VERSION "1.0 — BFMC CAN Bus Network"

NS_ :

BS_:

BU_: GATEWAY MOTION SENSOR LOGGER

BO_ 16 EMERGENCY_STOP: 2 Vector__XXX
 SG_ EStopSource : 0|8@1+ (1,0) [0|255] "" GATEWAY,MOTION,SENSOR,LOGGER
 SG_ EStopReason : 8|8@1+ (1,0) [0|255] "" GATEWAY,MOTION,SENSOR,LOGGER

BO_ 128 SAFETY_STATE: 2 GATEWAY
 SG_ ArmState : 0|8@1+ (1,0) [0|3] "" MOTION,SENSOR,LOGGER
 SG_ FaultFlags : 8|8@1+ (1,0) [0|255] "" MOTION,SENSOR,LOGGER

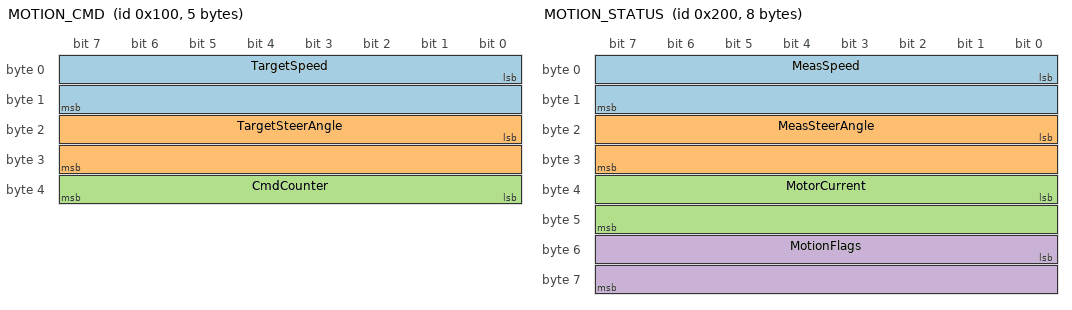
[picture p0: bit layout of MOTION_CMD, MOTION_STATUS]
BO_ 256 MOTION_CMD: 5 GATEWAY
 SG_ TargetSpeed : 0|16@1- (1,0) [-2000|2000] "mm/s" MOTION,LOGGER
 SG_ TargetSteerAngle : 16|16@1- (0.1,0) [-25|25] "deg" MOTION,LOGGER
 SG_ CmdCounter : 32|8@1+ (1,0) [0|255] "" MOTION,LOGGER

BO_ 512 MOTION_STATUS: 8 MOTION
 SG_ MeasSpeed : 0|16@1- (1,0) [-2000|2000] "mm/s" GATEWAY,LOGGER
 SG_ MeasSteerAngle : 16|16@1- (0.1,0) [-25|25] "deg" GATEWAY,LOGGER
 SG_ MotorCurrent : 32|16@1- (1,0) [-20000|20000] "mA" GATEWAY,LOGGER
 SG_ MotionFlags : 48|16@1+ (1,0) [0|65535] "" GATEWAY,LOGGER

BO_ 528 WHEEL_ENCODER: 8 MOTION
 SG_ EncoderTicks : 0|32@1- (1,0) [-2147483648|2147483647] "ticks" GATEWAY,LOGGER
 SG_ DistanceTravelled : 32|32@1- (1,0) [-2147483648|2147483647] "mm" GATEWAY,LOGGER

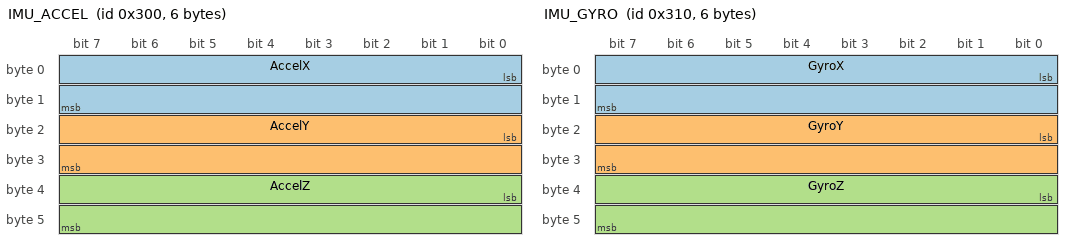
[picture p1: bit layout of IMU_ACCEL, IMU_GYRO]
BO_ 768 IMU_ACCEL: 6 SENSOR
 SG_ AccelX : 0|16@1- (1,0) [-8000|8000] "mg" GATEWAY,MOTION,LOGGER
 SG_ AccelY : 16|16@1- (1,0) [-8000|8000] "mg" GATEWAY,MOTION,LOGGER
 SG_ AccelZ : 32|16@1- (1,0) [-8000|8000] "mg" GATEWAY,MOTION,LOGGER

BO_ 784 IMU_GYRO: 6 SENSOR
 SG_ GyroX : 0|16@1- (0.1,0) [-2000|2000] "deg/s" GATEWAY,MOTION,LOGGER
 SG_ GyroY : 16|16@1- (0.1,0) [-2000|2000] "deg/s" GATEWAY,MOTION,LOGGER
 SG_ GyroZ : 32|16@1- (0.1,0) [-2000|2000] "deg/s" GATEWAY,MOTION,LOGGER

BO_ 800 IMU_ATTITUDE: 4 SENSOR
 SG_ Yaw : 0|16@1- (0.1,0) [-180|180] "deg" GATEWAY,MOTION,LOGGER
 SG_ YawRate : 16|16@1- (0.1,0) [-2000|2000] "deg/s" GATEWAY,MOTION,LOGGER

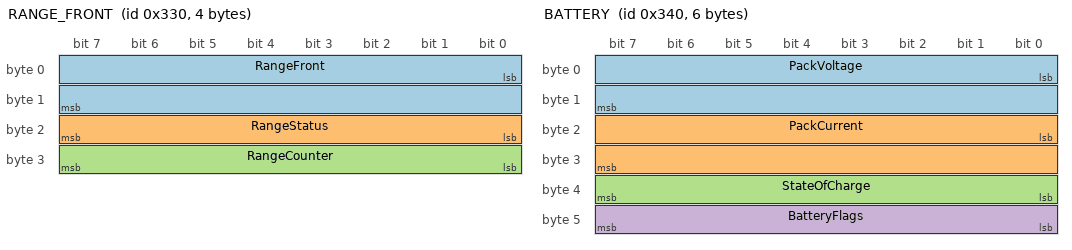
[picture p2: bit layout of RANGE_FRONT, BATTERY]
BO_ 816 RANGE_FRONT: 4 SENSOR
 SG_ RangeFront : 0|16@1+ (1,0) [0|4000] "mm" GATEWAY,MOTION,LOGGER
 SG_ RangeStatus : 16|8@1+ (1,0) [0|3] "" GATEWAY,MOTION,LOGGER
 SG_ RangeCounter : 24|8@1+ (1,0) [0|255] "" GATEWAY,MOTION,LOGGER

BO_ 832 BATTERY: 6 SENSOR
 SG_ PackVoltage : 0|16@1+ (1,0) [0|30000] "mV" GATEWAY,LOGGER
 SG_ PackCurrent : 16|16@1- (1,0) [-30000|30000] "mA" GATEWAY,LOGGER
 SG_ StateOfCharge : 32|8@1+ (1,0) [0|100] "%" GATEWAY,LOGGER
 SG_ BatteryFlags : 40|8@1+ (1,0) [0|255] "" GATEWAY,LOGGER

BO_ 1024 HB_GATEWAY: 2 GATEWAY
 SG_ GatewayHbCounter : 0|8@1+ (1,0) [0|255] "" MOTION,SENSOR,LOGGER
 SG_ GatewayNodeState : 8|8@1+ (1,0) [0|4] "" MOTION,SENSOR,LOGGER

BO_ 1025 HB_MOTION: 2 MOTION
 SG_ MotionHbCounter : 0|8@1+ (1,0) [0|255] "" GATEWAY,SENSOR,LOGGER
 SG_ MotionNodeState : 8|8@1+ (1,0) [0|4] "" GATEWAY,SENSOR,LOGGER

BO_ 1026 HB_SENSOR: 2 SENSOR
 SG_ SensorHbCounter : 0|8@1+ (1,0) [0|255] "" GATEWAY,MOTION,LOGGER
 SG_ SensorNodeState : 8|8@1+ (1,0) [0|4] "" GATEWAY,MOTION,LOGGER

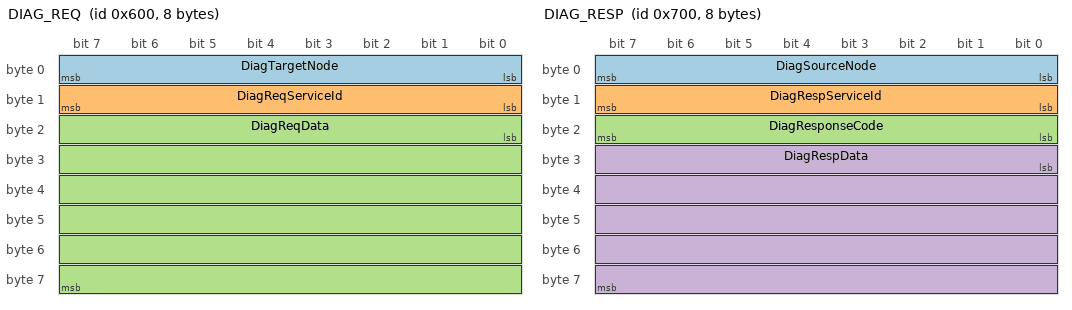
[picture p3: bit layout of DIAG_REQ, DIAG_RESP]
BO_ 1536 DIAG_REQ: 8 GATEWAY
 SG_ DiagTargetNode : 0|8@1+ (1,0) [0|255] "" MOTION,SENSOR,LOGGER
 SG_ DiagReqServiceId : 8|8@1+ (1,0) [0|255] "" MOTION,SENSOR,LOGGER
 SG_ DiagReqData : 16|48@1+ (1,0) [0|0] "" MOTION,SENSOR,LOGGER

BO_ 1792 DIAG_RESP: 8 Vector__XXX
 SG_ DiagSourceNode : 0|8@1+ (1,0) [0|255] "" GATEWAY,LOGGER
 SG_ DiagRespServiceId : 8|8@1+ (1,0) [0|255] "" GATEWAY,LOGGER
 SG_ DiagResponseCode : 16|8@1+ (1,0) [0|255] "" GATEWAY,LOGGER
 SG_ DiagRespData : 24|40@1+ (1,0) [0|0] "" GATEWAY,LOGGER

CM_ BO_ 16 "Broadcast emergency stop. Highest priority frame on the bus. Any node may originate.";
CM_ BO_ 128 "Vehicle-level arm state and aggregated fault bitfield, owned by the Gateway.";
CM_ BO_ 256 "Actuator setpoints. CmdCounter must advance every cycle or Motion rejects the frame as stale.";
CM_ BO_ 512 "Closed-loop feedback from the Motion ECU.";
CM_ BO_ 1536 "Diagnostic request, UDS-inspired. DiagTargetNode selects the addressed ECU.";
CM_ SG_ 256 CmdCounter "Rolling 0-255 counter. Detects a wedged sender that is still transmitting.";
CM_ SG_ 512 MotionFlags "Bit 0 ESTOP_ACTIVE, bit 1 CMD_TIMEOUT, bit 2 CMD_STALE, bit 3 OVERCURRENT, bit 4 ENCODER_FAULT.";

BA_DEF_ BO_  "GenMsgCycleTime" INT 0 65535;
BA_DEF_ BO_  "GenMsgSendType" ENUM  "Cyclic","Event";
BA_DEF_ BU_  "NodeAddress" INT 0 255;
BA_DEF_DEF_  "GenMsgCycleTime" 0;
BA_DEF_DEF_  "GenMsgSendType" "Cyclic";
BA_DEF_DEF_  "NodeAddress" 0;

BA_ "NodeAddress" BU_ GATEWAY 1;
BA_ "NodeAddress" BU_ MOTION 2;
BA_ "NodeAddress" BU_ SENSOR 3;
BA_ "NodeAddress" BU_ LOGGER 4;

BA_ "GenMsgSendType" BO_ 16 1;
BA_ "GenMsgCycleTime" BO_ 128 20;
BA_ "GenMsgCycleTime" BO_ 256 20;
BA_ "GenMsgCycleTime" BO_ 512 20;
BA_ "GenMsgCycleTime" BO_ 528 20;
BA_ "GenMsgCycleTime" BO_ 768 20;
BA_ "GenMsgCycleTime" BO_ 784 20;
BA_ "GenMsgCycleTime" BO_ 800 20;
BA_ "GenMsgCycleTime" BO_ 816 50;
BA_ "GenMsgCycleTime" BO_ 832 500;
BA_ "GenMsgCycleTime" BO_ 1024 100;
BA_ "GenMsgCycleTime" BO_ 1025 100;
BA_ "GenMsgCycleTime" BO_ 1026 100;
BA_ "GenMsgSendType" BO_ 1536 1;
BA_ "GenMsgSendType" BO_ 1792 1;

VAL_ 128 ArmState 0 "DISARMED" 1 "ARMING" 2 "ARMED" 3 "FAULT" ;
VAL_ 816 RangeStatus 0 "VALID" 1 "OUT_OF_RANGE" 2 "NO_ECHO" 3 "SENSOR_FAULT" ;
VAL_ 1024 GatewayNodeState 0 "INIT" 1 "RUNNING" 2 "DEGRADED" 3 "BUS_OFF" 4 "FAULT" ;
VAL_ 1025 MotionNodeState 0 "INIT" 1 "RUNNING" 2 "DEGRADED" 3 "BUS_OFF" 4 "FAULT" ;
VAL_ 1026 SensorNodeState 0 "INIT" 1 "RUNNING" 2 "DEGRADED" 3 "BUS_OFF" 4 "FAULT" ;
